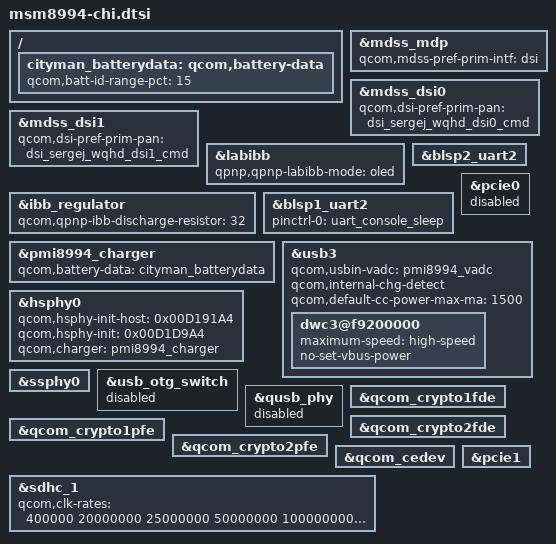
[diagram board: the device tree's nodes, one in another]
/* Copyright (c) 2014-2015, The Linux Foundation. All rights reserved.
 *
 * This program is free software; you can redistribute it and/or modify
 * it under the terms of the GNU General Public License version 2 and
 * only version 2 as published by the Free Software Foundation.
 *
 * This program is distributed in the hope that it will be useful,
 * but WITHOUT ANY WARRANTY; without even the implied warranty of
 * MERCHANTABILITY or FITNESS FOR A PARTICULAR PURPOSE.  See the
 * GNU General Public License for more details.
 */

#include "qcom/msm8994-pinctrl.dtsi"
#include "common/camera-cityman.dtsi"
#include "panels/dsi-panel-sergej-wqhd-dualdsi-cmd.dtsi"
#include "common/pinctrl.dtsi"
#include "common/connectivity.dtsi"
#include "common/sdhc.dtsi"
#include "common/haptics.dtsi"
#include "common/touch.dtsi"
#include "common/silabs.dtsi"
#include "common/sidekeys.dtsi"
#include "common/audio.dtsi"
#include "common/adc.dtsi"
#include "common/charger.dtsi"
#include "common/mdss.dtsi"
#include "common/hdmi.dtsi"
#include "common/reserved-memory.dtsi"
#include "common/regulator.dtsi"
#include "common/gpios.dtsi"
#include "common/torch.dtsi"
#include "common/sensors.dtsi"
#include "common/nfc.dtsi"

&mdss_mdp {
	qcom,mdss-pref-prim-intf = "dsi";
};

&mdss_dsi0 {
	qcom,dsi-pref-prim-pan = <&dsi_sergej_wqhd_dsi0_cmd>;
};

&mdss_dsi1 {
	qcom,dsi-pref-prim-pan = <&dsi_sergej_wqhd_dsi1_cmd>;
};

&labibb {
	status = "ok";
	qpnp,qpnp-labibb-mode = "oled";
};

&ibb_regulator {
	qcom,qpnp-ibb-discharge-resistor = <32>;
};

&blsp2_uart2 {
	status = "ok";
};

&blsp1_uart2 {
	status= "ok";
	pinctrl-names = "default";
	pinctrl-0 = <&uart_console_sleep>;
};

/{
	cityman_batterydata: qcom,battery-data {
		qcom,batt-id-range-pct = <15>;
		#include "battery/microsoft_bvt4d_3340mah.dtsi"
	};
};
&pmi8994_charger {
	qcom,battery-data = <&cityman_batterydata>;
};
&pcie0 {
	status = "disabled";
};

&usb3 {
	status = "ok";
	qcom,usbin-vadc = <&pmi8994_vadc>;
	qcom,internal-chg-detect;
	/*
	 * No Type-C driver reads the CC current of the USB-C port: let a
	 * computer port supply up to 1.5 A instead of the 500 mA of USB 2.0.
	 * The PMI8994 AICL backs off on ports that cannot.
	 */
	qcom,default-cc-power-max-ma = <1500>;
 
	dwc3@f9200000 {
		maximum-speed = "high-speed";
		no-set-vbus-power;
	};
};
 
 &hsphy0 {
	 status = "ok";
	qcom,hsphy-init-host = <0x00D191A4>;
	qcom,hsphy-init = <0x00D1D9A4>;
	qcom,charger = <&pmi8994_charger>;
 };
 
 &ssphy0 {
	 status = "ok";
 };

&usb_otg_switch {
	status = "disabled";
};

&qusb_phy {
	status = "disabled";
};

 &qcom_crypto1fde {
	status = "okay";
};

&qcom_crypto2fde {
	status = "okay";
};

&qcom_crypto1pfe {
	status = "okay";
};

&qcom_crypto2pfe {
	status = "okay";
 };

 &qcom_cedev {
	 status = "okay";
 };
 
&pcie1 {
	/delete-property/ qcom,ep-wakeirq;
};

/*
 * The common sdhc include carries the MSM8992 eMMC rates (172/344 MHz).
 * The MSM8994 SDCC1 clock only provides 192/384 MHz, so HS200/HS400
 * tuning failed and the card fell back to DDR52.
 */
&sdhc_1 {
	qcom,clk-rates = <400000 20000000 25000000 50000000 100000000 192000000 384000000>;
};
